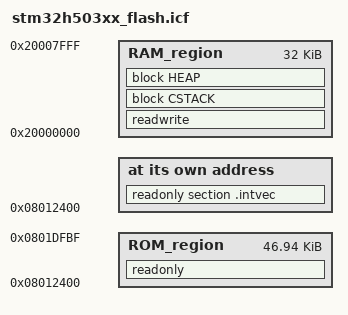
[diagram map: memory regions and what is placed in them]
/*###ICF### Section handled by ICF editor, don't touch! ****/
/*-Editor annotation file-*/
/* IcfEditorFile="$TOOLKIT_DIR$\config\ide\IcfEditor\cortex_v1_0.xml" */
/*-Specials-*/
define exported symbol CODE_OFFSET = 0x12000; /* This define is updated automatically from OEMiROT_BOOT project */
define exported symbol CODE_SIZE = 0xC000; /* This define is updated automatically from OEMiROT_BOOT project */
define exported symbol IMAGE_HEADER_SIZE = 0x400; /* mcuboot headre size */
define symbol TRAILER_MAX_SIZE = 0x40; /* Trailer max size */
define exported symbol __ICFEDIT_intvec_start__ = 0x08000000 + CODE_OFFSET + IMAGE_HEADER_SIZE;
/*-Memory Regions-*/
define symbol __ICFEDIT_region_ROM_start__ = 0x08000000 + CODE_OFFSET + IMAGE_HEADER_SIZE;
define symbol __ICFEDIT_region_ROM_end__   = 0x08000000 + CODE_OFFSET + CODE_SIZE - TRAILER_MAX_SIZE - 1;
define symbol __ICFEDIT_region_RAM_start__ = 0x20000000;
define symbol __ICFEDIT_region_RAM_end__   = 0x20007FFF;

/*-Sizes-*/
define symbol __ICFEDIT_size_cstack__ = 0x400;
define symbol __ICFEDIT_size_heap__   = 0x200;
/**** End of ICF editor section. ###ICF###*/


define memory mem with size = 4G;
define region ROM_region      = mem:[from __ICFEDIT_region_ROM_start__   to __ICFEDIT_region_ROM_end__];
define region RAM_region      = mem:[from __ICFEDIT_region_RAM_start__   to __ICFEDIT_region_RAM_end__];

define block CSTACK    with alignment = 8, size = __ICFEDIT_size_cstack__   { };
define block HEAP      with alignment = 8, size = __ICFEDIT_size_heap__     { };

initialize by copy { readwrite };
do not initialize  { section .noinit };

place at address mem:__ICFEDIT_intvec_start__ { readonly section .intvec };

place in ROM_region   { readonly };
place in RAM_region   { readwrite,
                        block CSTACK, block HEAP };
                        
